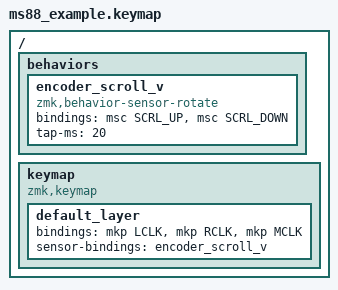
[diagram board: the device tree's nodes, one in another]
#include <behaviors.dtsi>
#include <dt-bindings/zmk/keys.h>
#include <dt-bindings/zmk/pointing.h>
#define ZMK_POINTING_DEFAULT_SCRL_VAL 120

/ {
    behaviors {
        encoder_scroll_v: encoder_scroll_v {
            compatible = "zmk,behavior-sensor-rotate";
            #sensor-binding-cells = <0>;
            bindings = <&msc SCRL_UP>, <&msc SCRL_DOWN>;
            tap-ms = <20>;
        };
    };

    keymap {
        compatible = "zmk,keymap";

        default_layer {
            bindings = <
                &mkp LCLK &mkp RCLK &mkp MCLK
            >;

            sensor-bindings = <&encoder_scroll_v>;
        };
    };
};
